AUTOSAR XML (schema 00044)
package /VehicleProject
  system System
    system mapping System_MPPNG
      data-mappings:
        data-element=rawCurrentData.rawCurrentData, system-signal=rawCurrentData
        data-element=DoorStatus.DoorStatus, system-signal=DoorStatus
    root-software-compositions:
      root sw composition prototype EcuSwComposition: software-composition=ECU_Composition
package /ECUCompositionTypes
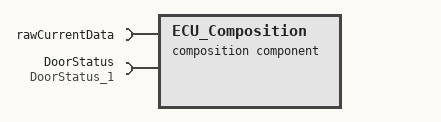
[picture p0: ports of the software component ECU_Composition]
  composition sw component type ECU_Composition
    require port rawCurrentData: nonqueued-receiver-com-spec{data-element=rawCurrentData, init-value=32768}, required-interface=rawCurrentData
    require port DoorStatus: nonqueued-receiver-com-spec{data-element=DoorStatus, init-value=0}, required-interface=DoorStatus_1
    component CurrentProcess: type=CurrentProcess
    component CurrentProcess2: type=CurrentProcess2
    delegate CurrentProcess.DoorStatus <-> outer port DoorStatus
    delegate CurrentProcess.rawCurrentData <-> outer port rawCurrentData
    delegate CurrentProcess2.rawCurrentData <-> outer port rawCurrentData
    delegate CurrentProcess2.DoorStatus <-> outer port DoorStatus
package /EndToEndProtections
  end to end protection set EndToEndProtectionSet
